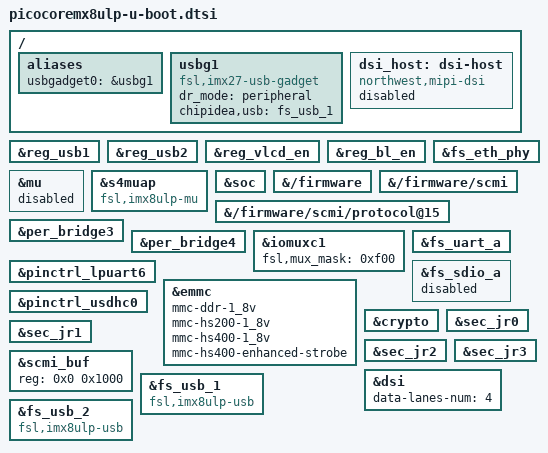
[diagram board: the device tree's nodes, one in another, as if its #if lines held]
// SPDX-License-Identifier: GPL-2.0
/*
* Copyright 2024 F&S Elektronik Systeme GmbH
*
* This program is free software; you can redistribute it and/or modify
* it under the terms of the GNU General Public License version 2 as
* published by the Free Software Foundation.
*
* This program is distributed in the hope that it will be useful,
* but WITHOUT ANY WARRANTY; without even the implied warranty of
* MERCHANTABILITY or FITNESS FOR A PARTICULAR PURPOSE.  See the
* GNU General Public License for more details.
*/

&{/aliases}{
	/delete-property/ serial2;
	/delete-property/ isi0;
	/delete-property/ csi0;
	/delete-property/ pwm0;

	/delete-property/ i2c3;
	/delete-property/ i2c4;
	/delete-property/ gpio0;
	/delete-property/ gpio1;
	/delete-property/ gpio2;
};

#if CONFIG_PICOCOREMX8ULP_REV >= 120
&reg_usb1 {
	/delete-property/ gpio;
};

&reg_usb2 {
	/delete-property/ gpio;
};

&reg_vlcd_en {
	/delete-property/ gpio;
};

&reg_bl_en {
	/delete-property/ gpio;
};

&fs_eth_phy {
	/delete-property/ reset-gpios;
	/delete-property/ interrupt-parent;
	/delete-property/ interrupts;
};
#endif

&mu {
	status = "disabled";
};

&s4muap {
		compatible = "fsl,imx8ulp-mu";
		bootph-all;
};

/ {
	aliases {
		usbgadget0 = &usbg1;
	};

	usbg1: usbg1 {
		compatible = "fsl,imx27-usb-gadget";
		dr_mode = "peripheral";
		chipidea,usb = <&fs_usb_1>;
		status = "okay";
	};

	dsi_host: dsi-host {
		compatible = "northwest,mipi-dsi";
		status = "disabled";
	};
};

&soc {
	bootph-all;
	bootph-pre-ram;
};

&{/firmware} {
	bootph-some-ram;
};

&{/firmware/scmi} {
	bootph-some-ram;
};

&{/firmware/scmi/protocol@15} {
	bootph-some-ram;
};

&per_bridge3 {
	bootph-all;
	bootph-pre-ram;
};

&per_bridge4 {
	bootph-all;
	bootph-pre-ram;
};

&iomuxc1 {
	bootph-all;
	bootph-pre-ram;
	fsl,mux_mask = <0xf00>;
};

#if CONFIG_PICOCOREMX8ULP_REV >= 120
&pinctrl_lpuart6 {
	bootph-all;
	bootph-pre-ram;
};
#else
&pinctrl_lpuart5 {
	bootph-all;
	bootph-pre-ram;
};
#endif

&fs_uart_a {
	bootph-all;
	bootph-pre-ram;
};

&emmc {
	bootph-pre-ram;
	/delete-property/ vmmc-supply;
	/delete-property/ vqmmc-supply;
	mmc-ddr-1_8v;
	mmc-hs200-1_8v;
	mmc-hs400-1_8v;
	mmc-hs400-enhanced-strobe;
};

&fs_sdio_a {
	/delete-property/ vmmc-supply;
	/delete-property/ vqmmc-supply;
	status = "disabled";
};

&pinctrl_usdhc0 {
	bootph-pre-ram;
};

&crypto {
	bootph-pre-ram;
};

&sec_jr0 {
	bootph-pre-ram;
};

&sec_jr1 {
	bootph-pre-ram;
};

&sec_jr2 {
	bootph-pre-ram;
};

&sec_jr3 {
	bootph-pre-ram;
};

&scmi_buf {
	reg = <0x0 0x1000>; /* Align page size */
};

&dsi {
	data-lanes-num = <4>;
};

&fs_usb_1 {
	compatible = "fsl,imx8ulp-usb", "fsl,imx7ulp-usb", "fsl,imx27-usb";
};

&fs_usb_2 {
	compatible = "fsl,imx8ulp-usb", "fsl,imx7ulp-usb", "fsl,imx27-usb";
};
